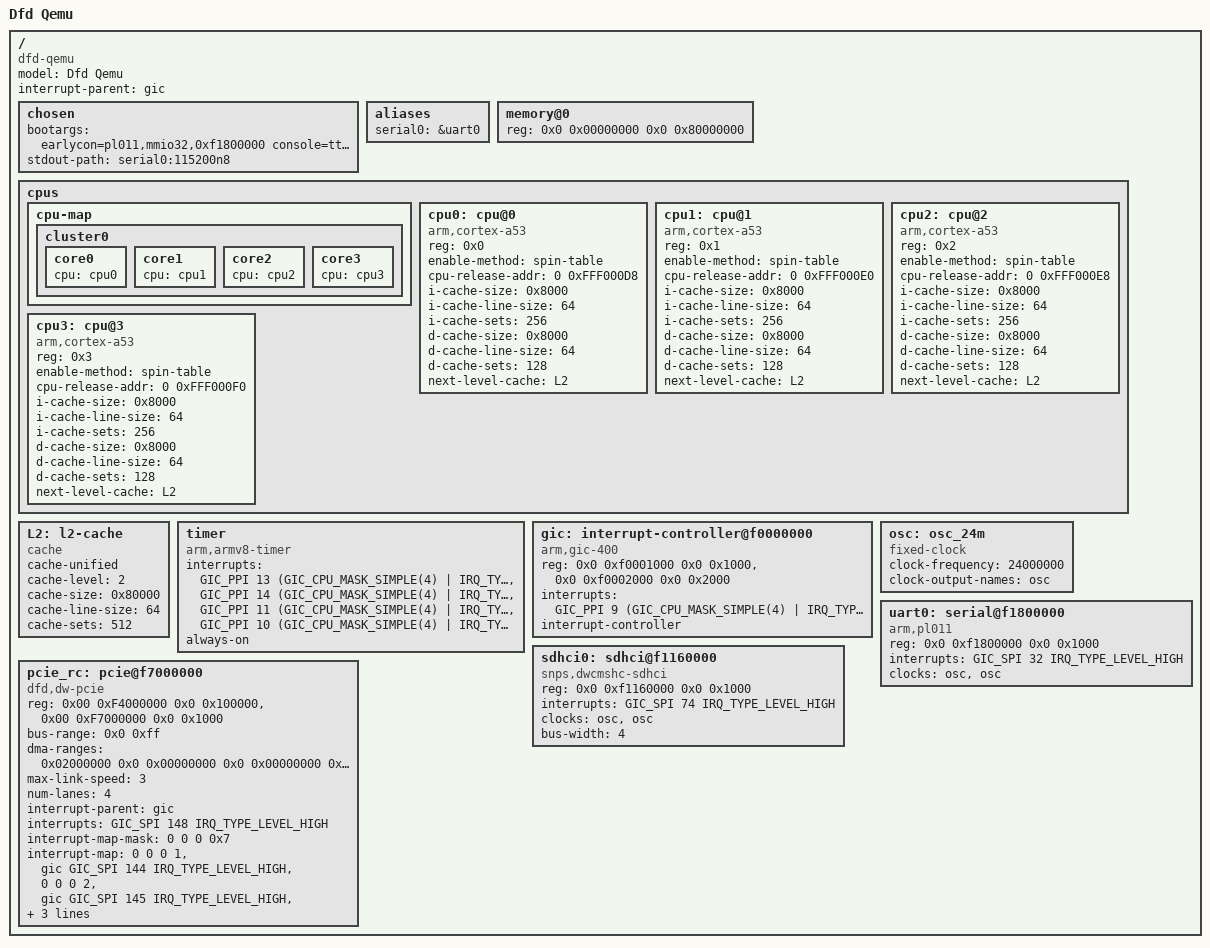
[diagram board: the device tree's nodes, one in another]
// SPDX-License-Identifier: (GPL-2.0+ OR MIT)

#include <dt-bindings/interrupt-controller/arm-gic.h>

/dts-v1/;
/ {
	compatible = "dfd-qemu";
	model = "Dfd Qemu";

	interrupt-parent = <&gic>;
	#address-cells = <2>;
	#size-cells = <2>;

	chosen {
		/*
		* enable early printk
		* "earlycon" or "earlycon=pl011,mmio32,0xf1800000"
		*
		* Do not unregister boot console at start. 一直使用早期printk
		* "keep_bootcon"
		*/
		//bootargs = "earlycon=pl011,mmio32,0xf1800000 console=ttyAMA0,115200n8 rootwait root=/dev/mmcblk0p2 rootfstype=ext4 rw";
		bootargs = "earlycon=pl011,mmio32,0xf1800000 console=ttyAMA0,115200n8 rootwait root=/dev/mmcblk0p2 rootfstype=ext4 rw";
		stdout-path = "serial0:115200n8";
	};

	aliases {
		serial0 = &uart0;
	};

	memory@0 {
		device_type = "memory";
		reg = <0x0 0x00000000 0x0 0x80000000>;
		status = "okay";
	};

	cpus {
		#address-cells = <1>;
		#size-cells = <0>;

		cpu-map {
			cluster0: cluster0 {
				core0 {
					cpu = <&cpu0>;
				};

				core1 {
					cpu = <&cpu1>;
				};

				core2 {
					cpu = <&cpu2>;
				};

				core3 {
					cpu = <&cpu3>;
				};
			};
		};

		cpu0: cpu@0 {
			device_type = "cpu";
			compatible = "arm,cortex-a53";
			reg = <0x0>;
			enable-method = "spin-table";
			cpu-release-addr = <0 0xFFF000D8>;
			i-cache-size = <0x8000>;
			i-cache-line-size = <64>;
			i-cache-sets = <256>;
			d-cache-size = <0x8000>;
			d-cache-line-size = <64>;
			d-cache-sets = <128>;
			next-level-cache = <&L2>;
			//clock-names = "pll0", "cpu_clk", "bus_clk";
		};

		cpu1: cpu@1 {
			device_type = "cpu";
			compatible = "arm,cortex-a53";
			reg = <0x1>;
			enable-method = "spin-table";
			cpu-release-addr = <0 0xFFF000E0>;
			i-cache-size = <0x8000>;
			i-cache-line-size = <64>;
			i-cache-sets = <256>;
			d-cache-size = <0x8000>;
			d-cache-line-size = <64>;
			d-cache-sets = <128>;
			next-level-cache = <&L2>;
		};

		cpu2: cpu@2 {
			device_type = "cpu";
			compatible = "arm,cortex-a53";
			reg = <0x2>;
			enable-method = "spin-table";
			cpu-release-addr = <0 0xFFF000E8>;
			i-cache-size = <0x8000>;
			i-cache-line-size = <64>;
			i-cache-sets = <256>;
			d-cache-size = <0x8000>;
			d-cache-line-size = <64>;
			d-cache-sets = <128>;
			next-level-cache = <&L2>;
		};

		cpu3: cpu@3 {
			device_type = "cpu";
			compatible = "arm,cortex-a53";
			reg = <0x3>;
			enable-method = "spin-table";
			cpu-release-addr = <0 0xFFF000F0>;
			i-cache-size = <0x8000>;
			i-cache-line-size = <64>;
			i-cache-sets = <256>;
			d-cache-size = <0x8000>;
			d-cache-line-size = <64>;
			d-cache-sets = <128>;
			next-level-cache = <&L2>;
		};
	};

	L2: l2-cache {
		compatible = "cache";
		cache-unified;
		cache-level = <2>;
		cache-size = <0x80000>;
		cache-line-size = <64>;
		cache-sets = <512>;
	};

	timer {
		compatible = "arm,armv8-timer";
		interrupts = <GIC_PPI 13 (GIC_CPU_MASK_SIMPLE(4) |
					  IRQ_TYPE_LEVEL_HIGH)>,
			     <GIC_PPI 14 (GIC_CPU_MASK_SIMPLE(4) |
					  IRQ_TYPE_LEVEL_HIGH)>,
			     <GIC_PPI 11 (GIC_CPU_MASK_SIMPLE(4) |
					  IRQ_TYPE_LEVEL_HIGH)>,
			     <GIC_PPI 10 (GIC_CPU_MASK_SIMPLE(4) |
					  IRQ_TYPE_LEVEL_HIGH)>;
		always-on;
	};

	gic: interrupt-controller@f0000000 {
		compatible = "arm,gic-400";
		reg = <0x0 0xf0001000 0x0 0x1000>, /* GICD */
		      <0x0 0xf0002000 0x0 0x2000>; /* GICC */

		      //<0x0 0xf0004000 0x0 0x1000>, /* GICH */
		      //<0x0 0xf0005000 0x0 0x1000>; /* GICV */
		interrupts = <GIC_PPI 9	(GIC_CPU_MASK_SIMPLE(4) | IRQ_TYPE_LEVEL_HIGH)>;
		interrupt-controller;
		#interrupt-cells = <3>;
		status = "okay";
	};

	osc: osc_24m {
		compatible = "fixed-clock";
		#clock-cells = <0>;
		clock-frequency = <24000000>;
		clock-output-names = "osc";
		status = "okay";
	};

	uart0: serial@f1800000 {
		compatible = "arm,pl011", "arm,primecell";
		reg = <0x0 0xf1800000 0x0 0x1000>;
		interrupts = <GIC_SPI 32 IRQ_TYPE_LEVEL_HIGH>;
		clocks = <&osc>, <&osc>;
		clock-names = "uartclk", "apb_pclk";
		status = "okay";
	};

	sdhci0: sdhci@f1160000 {
		compatible = "snps,dwcmshc-sdhci";
		reg = <0x0 0xf1160000 0x0 0x1000>;
		interrupts = <GIC_SPI 74 IRQ_TYPE_LEVEL_HIGH>;
		clocks = <&osc>, <&osc>;
		clock-names = "core", "bus";
		bus-width = <4>;
		status = "okay";
	};

	pcie_rc: pcie@f7000000 {
		compatible = "dfd,dw-pcie";
		reg = <0x00 0xF4000000 0x0 0x100000>,
		      <0x00 0xF7000000 0x0 0x1000>;
		reg-names = "config", "dbi";
		device_type = "pci";

		#address-cells = <3>;
		#size-cells = <2>;
		bus-range = <0x0 0xff>;
		ranges = <0x01000000 0x00 0x00000000 0x00 0xF5000000 0x0 0x00010000     /* IO memory 64KB */
			  0x02000000 0x00 0x00010000 0x00 0xF5010000 0x0 0x01FF0000     /* 32bit non-prefetchable memory 31MB */
			  0x43000000 0x00 0x02000000 0x22 0x40000000 0x0 0x40000000>;   /* 64bit prefetchable memory 1GB */
		/* in bound */
		dma-ranges = <0x02000000 0x0 0x00000000 0x0 0x00000000 0x0 0x20000000>;
		max-link-speed = <3>; /* 1: GEN1, 3: GEN3 */
		num-lanes = <4>;

		interrupt-parent = <&gic>;
		interrupts = <GIC_SPI 148 IRQ_TYPE_LEVEL_HIGH>;
		interrupt-names = "msi";

		#interrupt-cells = <1>;
		interrupt-map-mask = <0 0 0 0x7>;
		interrupt-map = <0 0 0 1 &gic GIC_SPI 144 IRQ_TYPE_LEVEL_HIGH>,
				<0 0 0 2 &gic GIC_SPI 145 IRQ_TYPE_LEVEL_HIGH>,
				<0 0 0 3 &gic GIC_SPI 146 IRQ_TYPE_LEVEL_HIGH>,
				<0 0 0 4 &gic GIC_SPI 147 IRQ_TYPE_LEVEL_HIGH>;
		status = "okay";
	};

};
